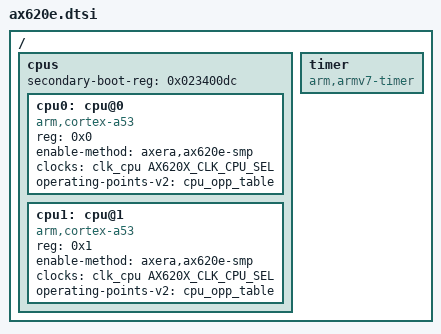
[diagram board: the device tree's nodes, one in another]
// SPDX-License-Identifier: GPL-2.0-or-later
/* AX620Q boots in AArch32 with the vendor holding-pen SMP protocol. */
#include "ax620e-common.dtsi"

/ {
	cpus {
		secondary-boot-reg = <0x023400dc>;
		#address-cells = <1>;
		#size-cells = <0>;

		cpu0: cpu@0 {
			device_type = "cpu";
			compatible = "arm,cortex-a53";
			reg = <0x0>;
			enable-method = "axera,ax620e-smp";
			clocks = <&clk_cpu AX620X_CLK_CPU_SEL>;
			operating-points-v2 = <&cpu_opp_table>;
		};

		cpu1: cpu@1 {
			device_type = "cpu";
			compatible = "arm,cortex-a53";
			reg = <0x1>;
			enable-method = "axera,ax620e-smp";
			clocks = <&clk_cpu AX620X_CLK_CPU_SEL>;
			operating-points-v2 = <&cpu_opp_table>;
		};
	};

    timer {
        compatible = "arm,armv7-timer";
    };

};

#include "ax620q-peripherals.dtsi"
